AUTOSAR XML (schema 4-3-0)
package /ComponentTypes
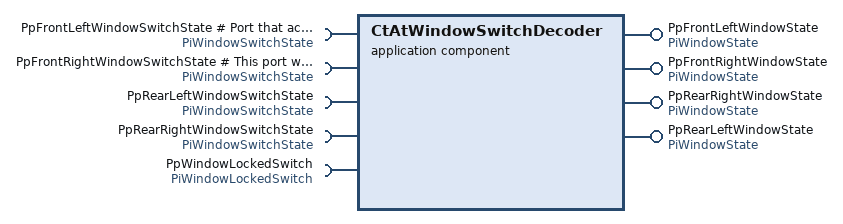
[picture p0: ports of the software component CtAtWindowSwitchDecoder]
  application sw component type CtAtWindowSwitchDecoder
    4 x require port, all with nonqueued-receiver-com-spec{data-element=DeWindowSwitchState, init-value=0}, required-interface=PiWindowSwitchState:
      PpFrontLeftWindowSwitchState  # Port that accepts values for the left front window.
      PpFrontRightWindowSwitchState  # This port will accept input from the front right SWC and will have the following two values: - '0' when not pressed - '1' when pressed
      PpRearLeftWindowSwitchState
      PpRearRightWindowSwitchState
    4 x provide port, all with provided-interface=PiWindowState:
      PpFrontLeftWindowState: nonqueued-sender-com-spec{data-element=DeWindowState, init-value=0}
      PpFrontRightWindowState: nonqueued-sender-com-spec=DeWindowState
      PpRearRightWindowState: nonqueued-sender-com-spec=DeWindowState
      PpRearLeftWindowState: nonqueued-sender-com-spec=DeWindowState
    require port PpWindowLockedSwitch: nonqueued-receiver-com-spec{data-element=DeWindowLock, init-value=0}, required-interface=PiWindowLockedSwitch  # This Port will accept incoming boolean value from the connected actuator. If the value returns yes(trigger) the runnable will run.
    behavior CtAtWindowSwitchDecoder_InternalBehavior
      5 x data received event:
        DRT_WindowSwitchDecoder_PpWindowLockedSwitch_DeWindowLock: start-on-event=LockedSwitchActive, data=PpWindowLockedSwitch.DeWindowLock
        DRT_FrontLeftButtonHold_PpFrontLeftWindowSwitchState_DeWindowSwitchState: start-on-event=FrontLeftButtonHold, data=PpFrontLeftWindowSwitchState.DeWindowSwitchState
        DRT_FrontRightButtonHold_PpFrontRightWindowSwitchState_DeWindowSwitchState: start-on-event=FrontRightButtonHold, data=PpFrontRightWindowSwitchState.DeWindowSwitchState
        DRT_RearLeftButtonHold_PpRearLeftWindowSwitchState_DeWindowSwitchState: start-on-event=RearLeftButtonHold, data=PpRearLeftWindowSwitchState.DeWindowSwitchState
        DRT_RearRightButtonHold_PpRearRightWindowSwitchState_DeWindowSwitchState: start-on-event=RearRightButtonHold, data=PpRearRightWindowSwitchState.DeWindowSwitchState
      5 x runnable:
        LockedSwitchActive  # This runnable will run when we get the value 'True' on 'WindowLockedState' port. The runnable will handle the locking of all window except the drivers window.
          data-receive-point-by-arguments:
            access REC_PpFrontRightWindowSwitchState_DeWindowSwitchState: accessed-variable=PpFrontRightWindowSwitchState.DeWindowSwitchState
            access REC_PpWindowLockedSwitch_DeWindowLock: accessed-variable=PpWindowLockedSwitch.DeWindowLock
          data-send-points:
            access SEND_PpFrontRightWindowState_DeWindowState: accessed-variable=PpFrontRightWindowState.DeWindowState
        FrontLeftButtonHold
          data-receive-point-by-arguments:
            access REC_PpFrontLeftWindowSwitchState_DeWindowSwitchState: accessed-variable=PpFrontLeftWindowSwitchState.DeWindowSwitchState
          data-send-points:
            access SEND_PpFrontLeftWindowState_DeWindowState: accessed-variable=PpFrontLeftWindowState.DeWindowState
        FrontRightButtonHold
          data-receive-point-by-arguments:
            access REC_PpFrontRightWindowSwitchState_DeWindowSwitchState: accessed-variable=PpFrontRightWindowSwitchState.DeWindowSwitchState
          data-send-points:
            access SEND_PpFrontRightWindowState_DeWindowState: accessed-variable=PpFrontRightWindowState.DeWindowState
        RearLeftButtonHold
          data-receive-point-by-arguments:
            access REC_PpRearLeftWindowSwitchState_DeWindowSwitchState: accessed-variable=PpRearLeftWindowSwitchState.DeWindowSwitchState
          data-send-points:
            access SEND_PpRearLeftWindowState_DeWindowState: accessed-variable=PpRearLeftWindowState.DeWindowState
        RearRightButtonHold
          data-receive-point-by-arguments:
            access REC_PpRearRightWindowSwitchState_DeWindowSwitchState: accessed-variable=PpRearRightWindowSwitchState.DeWindowSwitchState
          data-send-points:
            access SEND_PpRearRightWindowState_DeWindowState: accessed-variable=PpRearRightWindowState.DeWindowState
  swc implementation CtAtWindowSwitchDecoder_Implementation: behavior=CtAtWindowSwitchDecoder_InternalBehavior
